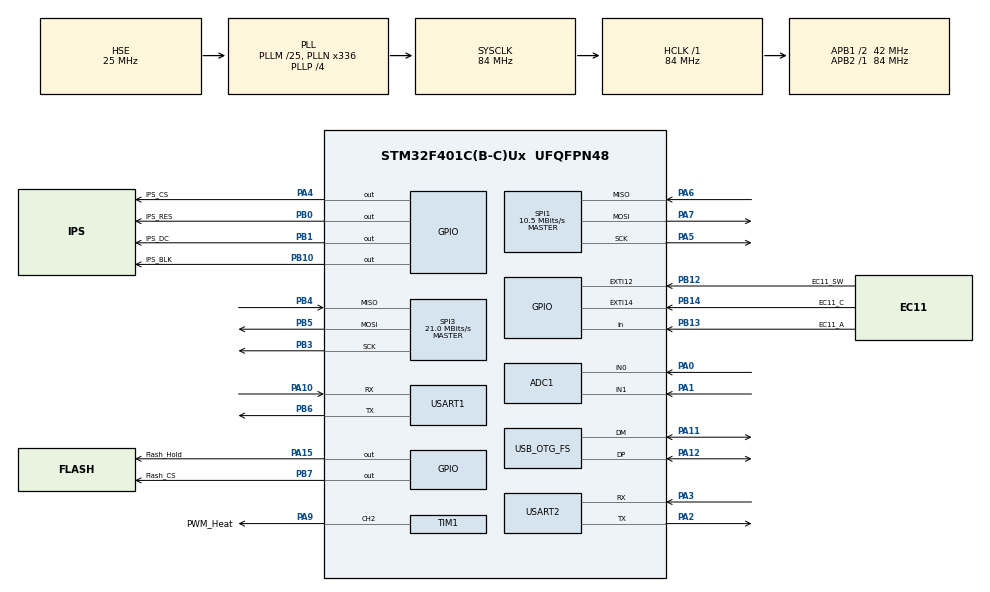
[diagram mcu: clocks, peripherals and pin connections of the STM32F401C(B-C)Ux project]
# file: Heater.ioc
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ADC1.Channel-0\#ChannelRegularConversion=ADC_CHANNEL_0
ADC1.Channel-1\#ChannelRegularConversion=ADC_CHANNEL_1
ADC1.ContinuousConvMode=ENABLE
ADC1.DMAContinuousRequests=ENABLE
ADC1.DiscontinuousConvMode=DISABLE
ADC1.EOCSelection=ADC_EOC_SEQ_CONV
ADC1.InjNumberOfConversion=0
ADC1.NbrOfConversion=2
ADC1.NbrOfConversionFlag=1
ADC1.Rank-0\#ChannelRegularConversion=1
ADC1.Rank-1\#ChannelRegularConversion=2
ADC1.SamplingTime-0\#ChannelRegularConversion=ADC_SAMPLETIME_112CYCLES
ADC1.SamplingTime-1\#ChannelRegularConversion=ADC_SAMPLETIME_112CYCLES
ADC1.ScanConvMode=ENABLE
ADC1.master=1
Dma.ADC1.0.Direction=DMA_PERIPH_TO_MEMORY
Dma.ADC1.0.FIFOMode=DMA_FIFOMODE_DISABLE
Dma.ADC1.0.Instance=DMA2_Stream0
Dma.ADC1.0.MemDataAlignment=DMA_MDATAALIGN_WORD
Dma.ADC1.0.MemInc=DMA_MINC_ENABLE
Dma.ADC1.0.Mode=DMA_CIRCULAR
Dma.ADC1.0.PeriphDataAlignment=DMA_PDATAALIGN_WORD
Dma.ADC1.0.PeriphInc=DMA_PINC_DISABLE
Dma.ADC1.0.Priority=DMA_PRIORITY_LOW
Dma.Request0=ADC1
FREERTOS.Tasks01=mainTask,0,1024,StartMainTask,Default,NULL,Dynamic,NULL,NULL;SubTask,-3,1024,StartSubTask,Default,NULL,Dynamic,NULL,NULL;Communication,-3,1024,StartCommunicate,Default,NULL,Dynamic,NULL,NULL
FREERTOS.configENABLE_FPU=1
Mcu.Family=STM32F4
Mcu.Name=STM32F401C(B-C)Ux
Mcu.Package=UFQFPN48
Mcu.UserConstants=UART2_WEB,1;SPI3_Flash,1;VirtualPort_DebugOutput,1;UART1_UpperClassControl,1;SPI1_IPS,1;ADC1_NTC,1
NVIC.ADC_IRQn=true\:5\:0\:false\:false\:true\:true\:true\:true\:true
NVIC.DMA2_Stream0_IRQn=true\:5\:0\:false\:false\:true\:false\:false\:true\:true
NVIC.EXTI15_10_IRQn=true\:5\:0\:false\:false\:true\:true\:true\:true\:true
NVIC.OTG_FS_IRQn=true\:5\:0\:false\:false\:true\:true\:false\:true\:true
NVIC.PriorityGroup=NVIC_PRIORITYGROUP_4
NVIC.TIM1_BRK_TIM9_IRQn=true\:5\:0\:false\:false\:true\:true\:true\:true\:true
NVIC.TIM1_TRG_COM_TIM11_IRQn=true\:15\:0\:false\:false\:true\:false\:false\:true\:true
NVIC.TimeBase=TIM1_TRG_COM_TIM11_IRQn
NVIC.TimeBaseIP=TIM11
PA0-WKUP.Signal=ADCx_IN0
PA1.Signal=ADCx_IN1
PA10.Mode=Asynchronous
PA10.Signal=USART1_RX
PA11.Mode=Device_Only
PA11.Signal=USB_OTG_FS_DM
PA12.Mode=Device_Only
PA12.Signal=USB_OTG_FS_DP
PA13.Mode=Serial_Wire
PA13.Signal=SYS_JTMS-SWDIO
PA14.Mode=Serial_Wire
PA14.Signal=SYS_JTCK-SWCLK
PA15.GPIO_Label=Flash_Hold
PA15.Signal=GPIO_Output
PA2.Mode=Asynchronous
PA2.Signal=USART2_TX
PA3.Mode=Asynchronous
PA3.Signal=USART2_RX
PA4.GPIO_Label=IPS_CS
PA4.GPIO_ModeDefaultOutputPP=GPIO_MODE_OUTPUT_PP
PA4.GPIO_PuPd=GPIO_NOPULL
PA4.GPIO_Speed=GPIO_SPEED_FREQ_VERY_HIGH
PA4.Signal=GPIO_Output
PA5.Mode=Full_Duplex_Master
PA5.Signal=SPI1_SCK
PA6.Mode=Full_Duplex_Master
PA6.Signal=SPI1_MISO
PA7.Mode=Full_Duplex_Master
PA7.Signal=SPI1_MOSI
PA9.GPIO_Label=PWM_Heat
PA9.Signal=S_TIM1_CH2
PB0.GPIO_Label=IPS_RES
PB0.Signal=GPIO_Output
PB1.GPIO_Label=IPS_DC
PB1.GPIO_ModeDefaultOutputPP=GPIO_MODE_OUTPUT_PP
PB1.GPIO_PuPd=GPIO_NOPULL
PB1.GPIO_Speed=GPIO_SPEED_FREQ_VERY_HIGH
PB1.Signal=GPIO_Output
PB10.GPIO_Label=IPS_BLK
PB10.GPIO_ModeDefaultOutputPP=GPIO_MODE_OUTPUT_OD
PB10.GPIO_PuPd=GPIO_PULLUP
PB10.GPIO_Speed=GPIO_SPEED_FREQ_VERY_HIGH
PB10.Signal=GPIO_Output
PB12.GPIO_Label=EC11_SW
PB12.GPIO_ModeDefaultEXTI=GPIO_MODE_IT_RISING_FALLING
PB12.GPIO_PuPd=GPIO_NOPULL
PB12.Signal=GPXTI12
PB13.GPIO_Label=EC11_A
PB13.Signal=GPIO_Input
PB14.GPIO_Label=EC11_C
PB14.GPIO_ModeDefaultEXTI=GPIO_MODE_IT_RISING
PB14.Signal=GPXTI14
PB3.Mode=Full_Duplex_Master
PB3.Signal=SPI3_SCK
PB4.Mode=Full_Duplex_Master
PB4.Signal=SPI3_MISO
PB5.Mode=Full_Duplex_Master
PB5.Signal=SPI3_MOSI
PB6.Mode=Asynchronous
PB6.Signal=USART1_TX
PB7.GPIO_Label=Flash_CS
PB7.Signal=GPIO_Output
PH0\ -\ OSC_IN.Mode=HSE-External-Oscillator
PH0\ -\ OSC_IN.Signal=RCC_OSC_IN
PH1\ -\ OSC_OUT.Mode=HSE-External-Oscillator
PH1\ -\ OSC_OUT.Signal=RCC_OSC_OUT
ProjectManager.HeapSize=0x200
ProjectManager.StackSize=0x400
ProjectManager.TargetToolchain=MDK-ARM V5.27
RCC.48MHZClocksFreq_Value=48000000
RCC.AHBFreq_Value=84000000
RCC.APB1CLKDivider=RCC_HCLK_DIV2
RCC.APB1Freq_Value=42000000
RCC.APB1TimFreq_Value=84000000
RCC.APB2Freq_Value=84000000
RCC.APB2TimFreq_Value=84000000
RCC.CortexFreq_Value=84000000
RCC.EnbaleCSS=true
RCC.HCLKFreq_Value=84000000
RCC.HSE_VALUE=25000000
RCC.HSI_VALUE=16000000
RCC.PLLM=25
RCC.PLLN=336
RCC.PLLP=RCC_PLLP_DIV4
RCC.PLLQ=7
RCC.RCC_RTC_Clock_Source=RCC_RTCCLKSOURCE_LSE
RCC.RCC_RTC_Clock_SourceVirtual=RCC_RTCCLKSOURCE_LSE
RCC.SYSCLKFreq_VALUE=84000000
RCC.SYSCLKSource=RCC_SYSCLKSOURCE_PLLCLK
RCC.VCOOutputFreq_Value=336000000
SH.ADCx_IN0.0=ADC1_IN0,IN0
SH.ADCx_IN1.0=ADC1_IN1,IN1
SH.S_TIM1_CH2.0=TIM1_CH2,PWM Generation2 CH2
SPI1.BaudRatePrescaler=SPI_BAUDRATEPRESCALER_8
SPI1.CLKPhase=SPI_PHASE_1EDGE
SPI1.CLKPolarity=SPI_POLARITY_LOW
SPI1.CalculateBaudRate=10.5 MBits/s
SPI1.Direction=SPI_DIRECTION_2LINES
SPI1.Mode=SPI_MODE_MASTER
SPI1.VirtualType=VM_MASTER
SPI3.CalculateBaudRate=21.0 MBits/s
SPI3.Direction=SPI_DIRECTION_2LINES
SPI3.Mode=SPI_MODE_MASTER
SPI3.VirtualType=VM_MASTER
TIM1.Channel-PWM\ Generation2\ CH2=TIM_CHANNEL_2
TIM1.Period=1000 - 1
TIM1.Prescaler=840 - 1
TIM9.Period=1000 - 1
TIM9.Prescaler=84-1
USART1.VirtualMode=VM_ASYNC
USART2.VirtualMode=VM_ASYNC
USB_DEVICE.CLASS_NAME_FS=CDC
USB_DEVICE.VirtualMode=Cdc
USB_DEVICE.VirtualModeFS=Cdc_FS
USB_OTG_FS.VirtualMode=Device_Only
VP_FREERTOS_VS_CMSIS_V1.Mode=CMSIS_V1
VP_SYS_VS_tim11.Mode=TIM11
VP_TIM9_VS_ClockSourceINT.Mode=Internal
VP_USB_DEVICE_VS_USB_DEVICE_CDC_FS.Mode=CDC_FS
board=custom

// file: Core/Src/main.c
/* USER CODE BEGIN Header */
/**
  ******************************************************************************
  * @file           : main.c
  * @brief          : Main program body
  ******************************************************************************
  * @attention
  *
  * <h2><center>&copy; Copyright (c) 2022 STMicroelectronics.
  * All rights reserved.</center></h2>
  *
  * This software component is licensed by ST under Ultimate Liberty license
  * SLA0044, the "License"; You may not use this file except in compliance with
  * the License. You may obtain a copy of the License at:
  *                             www.st.com/SLA0044
  *
  ******************************************************************************
  */
/* USER CODE END Header */
#include "main.h"
#include "cmsis_os.h"
#include "adc.h"
#include "dma.h"
#include "spi.h"
#include "tim.h"
#include "usart.h"
#include "usb_device.h"
#include "gpio.h"

/* USER CODE BEGIN Includes */
#include "usbd_cdc_if.h"
#include "process.h"
/* USER CODE END Includes */

void SystemClock_Config(void);
void MX_FREERTOS_Init(void);

int main(void)
{

  /* MCU Configuration--------------------------------------------------------*/

  /* Reset of all peripherals, Initializes the Flash interface and the Systick. */
  HAL_Init();

  /* Configure the system clock */
  SystemClock_Config();

  /* USER CODE BEGIN SysInit */

  MX_DMA_Init();
  /* USER CODE END SysInit */

  /* Initialize all configured peripherals */
  MX_GPIO_Init();
  MX_USART1_UART_Init();
  MX_USART2_UART_Init();
  MX_SPI3_Init();
  MX_ADC1_Init();
  MX_SPI1_Init();
  MX_TIM1_Init();
  MX_DMA_Init();
  MX_TIM9_Init();

  /* Call init function for freertos objects (in freertos.c) */
  MX_FREERTOS_Init();

  /* Start scheduler */
  osKernelStart();

  /* We should never get here as control is now taken by the scheduler */
  /* Infinite loop */
  while (1)
  {

  }
}

void SystemClock_Config(void)
{
  RCC_OscInitTypeDef RCC_OscInitStruct = {0};
  RCC_ClkInitTypeDef RCC_ClkInitStruct = {0};

  /** Configure the main internal regulator output voltage
  */
  __HAL_RCC_PWR_CLK_ENABLE();
  __HAL_PWR_VOLTAGESCALING_CONFIG(PWR_REGULATOR_VOLTAGE_SCALE2);

  /** Initializes the RCC Oscillators according to the specified parameters
  * in the RCC_OscInitTypeDef structure.
  */
  RCC_OscInitStruct.OscillatorType = RCC_OSCILLATORTYPE_HSE;
  RCC_OscInitStruct.HSEState = RCC_HSE_ON;
  RCC_OscInitStruct.PLL.PLLState = RCC_PLL_ON;
  RCC_OscInitStruct.PLL.PLLSource = RCC_PLLSOURCE_HSE;
  RCC_OscInitStruct.PLL.PLLM = 25;
  RCC_OscInitStruct.PLL.PLLN = 336;
  RCC_OscInitStruct.PLL.PLLP = RCC_PLLP_DIV4;
  RCC_OscInitStruct.PLL.PLLQ = 7;
  if (HAL_RCC_OscConfig(&RCC_OscInitStruct) != HAL_OK)
  {
    Error_Handler();
  }

  /** Initializes the CPU, AHB and APB buses clocks
  */
  RCC_ClkInitStruct.ClockType = RCC_CLOCKTYPE_HCLK|RCC_CLOCKTYPE_SYSCLK
                              |RCC_CLOCKTYPE_PCLK1|RCC_CLOCKTYPE_PCLK2;
  RCC_ClkInitStruct.SYSCLKSource = RCC_SYSCLKSOURCE_PLLCLK;
  RCC_ClkInitStruct.AHBCLKDivider = RCC_SYSCLK_DIV1;
  RCC_ClkInitStruct.APB1CLKDivider = RCC_HCLK_DIV2;
  RCC_ClkInitStruct.APB2CLKDivider = RCC_HCLK_DIV1;

  if (HAL_RCC_ClockConfig(&RCC_ClkInitStruct, FLASH_LATENCY_2) != HAL_OK)
  {
    Error_Handler();
  }

  /** Enables the Clock Security System
  */
  HAL_RCC_EnableCSS();
}

void HAL_TIM_PeriodElapsedCallback(TIM_HandleTypeDef *htim)
{
  if (htim->Instance == TIM11) {
    HAL_IncTick();
  }
  /* USER CODE BEGIN Callback 1 */
  if (htim->Instance == TIM9) {
    Process_Circular_Run();
  }

  /* USER CODE END Callback 1 */
}

void Error_Handler(void)
{
  __disable_irq();
  while (1)
  {
  }
}

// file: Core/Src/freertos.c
/* USER CODE BEGIN Header */
/**
  ******************************************************************************
  * File Name          : freertos.c
  * Description        : Code for freertos applications
  ******************************************************************************
  * @attention
  *
  * Copyright (c) 2022 STMicroelectronics.
  * All rights reserved.
  *
  * This software is licensed under terms that can be found in the LICENSE file
  * in the root directory of this software component.
  * If no LICENSE file comes with this software, it is provided AS-IS.
  *
  ******************************************************************************
  */
/* USER CODE END Header */

#include "FreeRTOS.h"
#include "task.h"
#include "main.h"
#include "cmsis_os.h"

/* USER CODE BEGIN Includes */
#include "usbd_cdc_if.h"
#include "gpio.h"
#include "process.h"
/* USER CODE END Includes */

/* USER CODE BEGIN Variables */

extern uint8_t get_data_flag;
extern uint8_t buf[];
extern uint32_t data_nums;
/* USER CODE END Variables */
osThreadId mainTaskHandle;
osThreadId SubTaskHandle;
osThreadId CommunicationHandle;

void StartMainTask(void const * argument);
void StartSubTask(void const * argument);
void StartCommunicate(void const * argument);

extern void MX_USB_DEVICE_Init(void);
void MX_FREERTOS_Init(void); /* (MISRA C 2004 rule 8.1) */

/* GetIdleTaskMemory prototype (linked to static allocation support) */
void vApplicationGetIdleTaskMemory( StaticTask_t **ppxIdleTaskTCBBuffer, StackType_t **ppxIdleTaskStackBuffer, uint32_t *pulIdleTaskStackSize );

/* USER CODE BEGIN GET_IDLE_TASK_MEMORY */
static StaticTask_t xIdleTaskTCBBuffer;
static StackType_t xIdleStack[configMINIMAL_STACK_SIZE];

void vApplicationGetIdleTaskMemory( StaticTask_t **ppxIdleTaskTCBBuffer, StackType_t **ppxIdleTaskStackBuffer, uint32_t *pulIdleTaskStackSize )
{
  *ppxIdleTaskTCBBuffer = &xIdleTaskTCBBuffer;
  *ppxIdleTaskStackBuffer = &xIdleStack[0];
  *pulIdleTaskStackSize = configMINIMAL_STACK_SIZE;
  /* place for user code */
}
/* USER CODE END GET_IDLE_TASK_MEMORY */

void MX_FREERTOS_Init(void) {

  /* Create the thread(s) */
  /* definition and creation of mainTask */
  osThreadDef(mainTask, StartMainTask, osPriorityNormal, 0, 1024);
  mainTaskHandle = osThreadCreate(osThread(mainTask), NULL);

  /* definition and creation of SubTask */
  osThreadDef(SubTask, StartSubTask, osPriorityIdle, 0, 1024);
  SubTaskHandle = osThreadCreate(osThread(SubTask), NULL);

  /* definition and creation of Communication */
  osThreadDef(Communication, StartCommunicate, osPriorityIdle, 0, 1024);
  CommunicationHandle = osThreadCreate(osThread(Communication), NULL);

}

void StartMainTask(void const * argument)
{
  /* init code for USB_DEVICE */
  MX_USB_DEVICE_Init();
  /* USER CODE BEGIN StartMainTask */
    Process_Main_Init();
    Process_Main_Run();
  /* Infinite loop */
  for(;;)
  {
    osDelay(1);
  }
  /* USER CODE END StartMainTask */
}

void StartSubTask(void const * argument)
{
  for(;;)
  {
    osDelay(1);
  }
}

void StartCommunicate(void const * argument)
{
  for(;;)
  {
    osDelay(1);
  }
}
